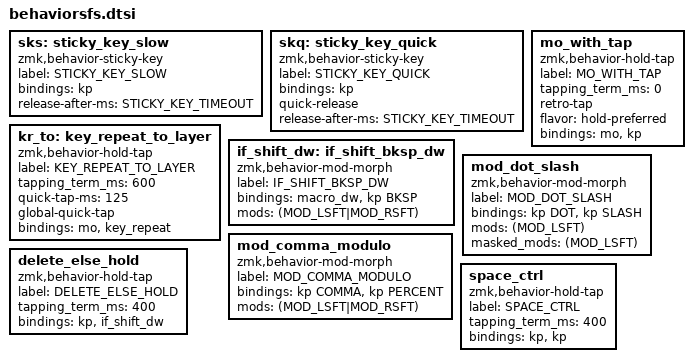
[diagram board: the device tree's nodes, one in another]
sks: sticky_key_slow {
	compatible = "zmk,behavior-sticky-key";
	label = "STICKY_KEY_SLOW";
	#binding-cells = <1>;
	bindings = <&kp>;
	// quick-release;
	release-after-ms = <STICKY_KEY_TIMEOUT>;
};
skq: sticky_key_quick {
	compatible = "zmk,behavior-sticky-key";
	label = "STICKY_KEY_QUICK";
	#binding-cells = <1>;
	bindings = <&kp>;
	quick-release;
	release-after-ms = <STICKY_KEY_TIMEOUT>;
};

// Sticky key on tap, normal key on hold
// Useful for modifier-clicking without the modifier remaining active
// nk: not_so_sticky_key {
//   compatible = "zmk,behavior-hold-tap";
//   label = "NOT_SO_STICKY_KEY";
//   #binding-cells = <2>;
//   tapping_term_ms = <200>;
//   flavor = "tap-preferred";
//   bindings = <&kp>, <&sk>;
// };
ooo

// A hold-tap that activates without delay (like `&mo`)
mo_tap: mo_with_tap {
	compatible = "zmk,behavior-hold-tap";
	label = "MO_WITH_TAP";
	#binding-cells = <2>;
	tapping_term_ms = <0>;
	retro-tap;
	flavor = "hold-preferred";
	bindings = <&mo>, <&kp>;
};

kr_to: key_repeat_to_layer {
	compatible = "zmk,behavior-hold-tap";
	label = "KEY_REPEAT_TO_LAYER";
	#binding-cells = <2>;
	tapping_term_ms = <600>;
	quick-tap-ms = <125>;
    global-quick-tap;
	bindings = <&mo>, <&key_repeat>;
};

if_shift_dw: if_shift_bksp_dw {
	compatible = "zmk,behavior-mod-morph";
	label = "IF_SHIFT_BKSP_DW";
	#binding-cells = <0>;
	bindings = <&macro_dw>, <&kp BKSP>;
	mods = <(MOD_LSFT|MOD_RSFT)>;
};

mod_dot_slash: mod_dot_slash {
	compatible = "zmk,behavior-mod-morph";
	label = "MOD_DOT_SLASH";
	#binding-cells = <0>;
	bindings = <&kp DOT>, <&kp SLASH>;
	mods = <(MOD_LSFT)>;
	masked_mods = <(MOD_LSFT)>;
};

mod_comma_modulo: mod_comma_modulo {
	compatible = "zmk,behavior-mod-morph";
	label = "MOD_COMMA_MODULO";
	#binding-cells = <0>;
	bindings = <&kp COMMA>, <&kp PERCENT>;
	mods = <(MOD_LSFT|MOD_RSFT)>;
};

delete_else_hold: delete_else_hold {
	compatible = "zmk,behavior-hold-tap";
	label = "DELETE_ELSE_HOLD";
	#binding-cells = <2>;
	tapping_term_ms = <400>;
	bindings = <&kp>, <&if_shift_dw>;
};

space_ctrl: space_ctrl {
	compatible = "zmk,behavior-hold-tap";
	label = "SPACE_CTRL";
	#binding-cells = <2>;
	tapping_term_ms = <400>;
	bindings = <&kp>, <&kp>;
};

// if_lctrl: if_lctrl {
//     compatible = "zmk,behavior-mod-morph";
//     label = "IF_LCTRL";
//     #binding-cells = <0>;
//     bindings = <&to BASE>, <&kp 0>;
//     mods = <(MOD_LCTL)>;
// };

// mo_to: mo_to {
//     compatible = "zmk,behavior-hold-tap";
//     label = "MO_TO";
//     #binding-cells = <2>;
//     tapping_term_ms = <200>;
//     bindings = <&mo>, <&to>;
// };
